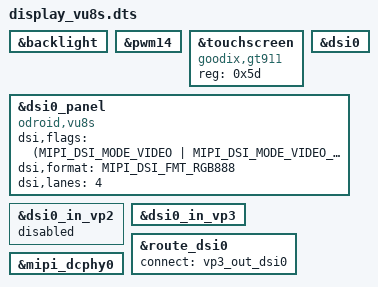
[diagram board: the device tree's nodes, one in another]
/dts-v1/;
/plugin/;

#include <dt-bindings/gpio/gpio.h>
#include <dt-bindings/pinctrl/rockchip.h>
#include <dt-bindings/display/drm_mipi_dsi.h>
#include <dt-bindings/display/rockchip_vop.h>
#include <dt-bindings/interrupt-controller/irq.h>
#include <dt-bindings/interrupt-controller/arm-gic.h>

/{
	fragment@0 {
		target = <&backlight>;

		__overlay__ {
			status = "okay";
		};
	};

	fragment@1 {
		target = <&pwm14>;

		__overlay__ {
			status = "okay";
		};
	};

	fragment@3 {
		target = <&touchscreen>;

		#address-cells = <1>;
		#size-cells = <0>;

		__overlay__ {
			status = "okay";

			compatible = "goodix,gt911";
			reg = <0x5d>;
		};
	};

	fragment@4 {
		target = <&dsi0>;

		__overlay__ {
			status = "okay";
		};
	};

	fragment@5 {
		target = <&dsi0_panel>;

		__overlay__ {
			status = "okay";
			compatible = "odroid,vu8s";

			dsi,flags = <(MIPI_DSI_MODE_VIDEO | MIPI_DSI_MODE_VIDEO_BURST |
					MIPI_DSI_MODE_NO_EOT_PACKET)>;
			dsi,format = <MIPI_DSI_FMT_RGB888>;
			dsi,lanes = <4>;
		};
	};

	fragment@6 {
		target = <&dsi0_in_vp2>;

		__overlay__ {
			status = "disabled";
		};
	};

	fragment@7 {
		target = <&dsi0_in_vp3>;

		__overlay__ {
			status = "okay";
		};
	};

	fragment@8 {
		target = <&route_dsi0>;

		__overlay__ {
			status = "okay";
			connect = <&vp3_out_dsi0>;
		};
	};

	fragment@10 {
		target = <&mipi_dcphy0>;

		__overlay__ {
			status = "okay";
		};
	};

	fragment@11 {
		target = <&route_dsi0>;

		__overlay__ {
			status = "okay";
		};
	};
};
